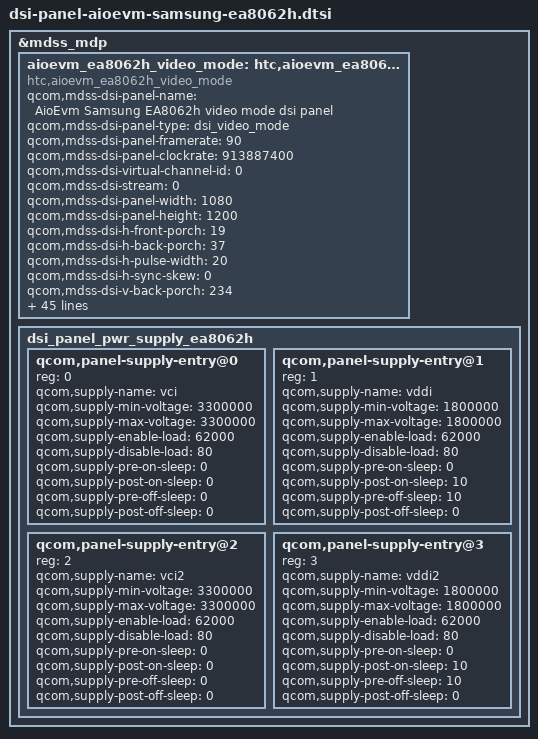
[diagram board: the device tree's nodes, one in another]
/* Copyright (c) 2014-2015, The Linux Foundation. All rights reserved.
 *
 * This program is free software; you can redistribute it and/or modify
 * it under the terms of the GNU General Public License version 2 and
 * only version 2 as published by the Free Software Foundation.
 *
 * This program is distributed in the hope that it will be useful,
 * but WITHOUT ANY WARRANTY; without even the implied warranty of
 * MERCHANTABILITY or FITNESS FOR A PARTICULAR PURPOSE.  See the
 * GNU General Public License for more details.
 */

&mdss_mdp {
    aioevm_ea8062h_video_mode: htc,aioevm_ea8062h_video_mode {
        compatible = "htc,aioevm_ea8062h_video_mode";
        qcom,mdss-dsi-panel-name = "AioEvm Samsung EA8062h video mode dsi panel";
        qcom,mdss-dsi-panel-type = "dsi_video_mode";
        qcom,mdss-dsi-panel-framerate = <90>;
        qcom,mdss-dsi-panel-clockrate = <913887400>;
        qcom,mdss-dsi-virtual-channel-id = <0>;
        qcom,mdss-dsi-stream = <0>;
        qcom,mdss-dsi-panel-width = <1080>;
        qcom,mdss-dsi-panel-height = <1200>;
        qcom,mdss-dsi-h-front-porch = <19>;
        qcom,mdss-dsi-h-back-porch = <37>;
        qcom,mdss-dsi-h-pulse-width = <20>;
        qcom,mdss-dsi-h-sync-skew = <0>;
        qcom,mdss-dsi-v-back-porch = <234>;
        qcom,mdss-dsi-v-front-porch = <28>;
        qcom,mdss-dsi-v-pulse-width = <2>;
        qcom,mdss-dsi-h-left-border = <0>;
        qcom,mdss-dsi-h-right-border = <0>;
        qcom,mdss-dsi-v-top-border = <0>;
        qcom,mdss-dsi-v-bottom-border = <0>;
        qcom,mdss-pan-physical-width-dimension  = <61>;
        qcom,mdss-pan-physical-height-dimension = <68>;
        qcom,mdss-dsi-bpp = <24>;
        qcom,mdss-dsi-color-order = "rgb_swap_rgb";
        qcom,mdss-dsi-underflow-color = <0xff>;
        qcom,mdss-dsi-border-color = <0>;
        qcom,mdss-dsi-h-sync-pulse = <0>;
        qcom,mdss-dsi-traffic-mode = "burst_mode";
        qcom,mdss-dsi-bllp-eof-power-mode;
        qcom,mdss-dsi-bllp-power-mode;
        qcom,mdss-dsi-tx-eot-append;
        qcom,mdss-dsi-lane-0-state;
        qcom,mdss-dsi-lane-1-state;
        qcom,mdss-dsi-lane-2-state;
        qcom,mdss-dsi-lane-3-state;
        qcom,mdss-dsi-dma-trigger = "trigger_sw";
        qcom,mdss-dsi-panel-timings = [D6 32 22 00 62 66 26 36 28 03 04 00]; /* Redundant for msm8996 */

        qcom,mdss-dsi-panel-timings-phy-v2 = [
            24 1F 08 09 05 03 04 a0
            24 1F 08 09 05 03 04 a0
            24 1F 08 09 05 03 04 a0
            24 1F 08 09 05 03 04 a0
            24 1C 08 09 05 03 04 a0    // Clk Lane
        ];
        qcom,mdss-dsi-t-clk-post = <0x0E>;
        qcom,mdss-dsi-t-clk-pre = <0x31>;

        qcom,mdss-dsi-reset-sequence = <1 1>, <0 1>, <1 10>;
        qcom,mdss-dsi-bl-pmic-control-type = "bl_ctrl_dcs";
        qcom,mdss-dsi-bl-min-level = <1>;
        qcom,mdss-dsi-bl-max-level = <255>;
        qcom,cmd-sync-wait-broadcast;

        qcom,mdss-dsi-on-command = [
            39 01 00 00 00 00 03 F0 5A 5A /* LEVEL 2 KEY Unlock */
            39 01 00 00 00 00 0A F2 00 00 00 00 00 04 38 04 B0 /* Resolution Setting */
            39 01 00 00 00 00 05 B2 04 C3 04 C3 /* AID Control (GI 16.6%) */
            39 01 00 00 00 00 03 B9 36 15 /* Source Control */
            39 01 00 00 00 00 03 C1 00 20 /* Pentile Control */
            39 01 00 00 00 00 03 F4 02 10 /* Power Control */
            39 01 00 00 00 00 08 B8 00 5A 74 03 00 00 19 /* VLIN1 Control */
            39 01 00 00 00 00 02 F7 01 /* Ltps Update */
            39 01 00 00 00 00 03 F0 A5 A5 /* LEVEL 2 KEY Lock */
            39 01 00 00 00 00 02 53 20  /* Dimming Control */
            39 01 00 00 00 00 02 51 8C /* WRDISBV ( 137 nits ) */
            39 01 00 00 00 00 03 FC 5A 5A /* LEVEL 3 KEY Unlock */
            39 01 00 00 00 00 02 B0 05 /* Global para */
            39 01 00 00 00 00 02 D1 80 /* OTP loading */
            39 01 00 00 78 00 02 11 00 /* Sleep Out & Delay 120 ms*/
            39 01 00 00 00 00 03 FC A5 A5 /* LEVEL 3 KEY Lock */
            39 01 00 00 00 00 03 F1 5A 5A /* OTP KEY Unlock */
            39 01 00 00 00 00 02 B0 01 /* Global para */
            39 01 00 00 00 00 02 CC 0A  /* TE pin normally low */
            39 01 00 00 00 00 03 F1 5A 5A /* OTP KEY Lock */
            39 01 00 00 00 00 02 29 00 /* Display On */
        ];

        qcom,mdss-dsi-off-command = [
            39 01 00 00 00 23 02 28 00 /* Display Off  & Delay 35 ms*/
            39 01 00 00 00 78 02 10 00 /* Sleep In & Delay 120 ms*/
        ];

        qcom,panel-supply-entries = <&dsi_panel_pwr_supply_ea8062h>;
        qcom,mdss-dsi-on-command-state = "dsi_lp_mode";
        qcom,mdss-dsi-off-command-state = "dsi_lp_mode";
        qcom,cont-splash-enabled;
        qcom,mdss-dsi-lp11-init;
        htc,mdss-dsi-lp11-init-delay-us = <25000>;
    };

    dsi_panel_pwr_supply_ea8062h: dsi_panel_pwr_supply_ea8062h {
        #address-cells = <1>;
        #size-cells = <0>;

        qcom,panel-supply-entry@0 {
            reg = <0>;
            qcom,supply-name = "vci";
            qcom,supply-min-voltage = <3300000>;
            qcom,supply-max-voltage = <3300000>;
            qcom,supply-enable-load = <62000>;
            qcom,supply-disable-load = <80>;
            qcom,supply-pre-on-sleep = <0>;
            qcom,supply-post-on-sleep = <0>;
            qcom,supply-pre-off-sleep = <0>;
            qcom,supply-post-off-sleep = <0>;
        };

        qcom,panel-supply-entry@1 {
            reg = <1>;
            qcom,supply-name = "vddi";
            qcom,supply-min-voltage = <1800000>;
            qcom,supply-max-voltage = <1800000>;
            qcom,supply-enable-load = <62000>;
            qcom,supply-disable-load = <80>;
            qcom,supply-pre-on-sleep = <0>;
            qcom,supply-post-on-sleep = <10>; //10ms
            qcom,supply-pre-off-sleep = <10>; //10ms
            qcom,supply-post-off-sleep = <0>;
        };
        qcom,panel-supply-entry@2 {
            reg = <2>;
            qcom,supply-name = "vci2";
            qcom,supply-min-voltage = <3300000>;
            qcom,supply-max-voltage = <3300000>;
            qcom,supply-enable-load = <62000>;
            qcom,supply-disable-load = <80>;
            qcom,supply-pre-on-sleep = <0>;
            qcom,supply-post-on-sleep = <0>;
            qcom,supply-pre-off-sleep = <0>;
            qcom,supply-post-off-sleep = <0>;
        };

        qcom,panel-supply-entry@3 {
            reg = <3>;
            qcom,supply-name = "vddi2";
            qcom,supply-min-voltage = <1800000>;
            qcom,supply-max-voltage = <1800000>;
            qcom,supply-enable-load = <62000>;
            qcom,supply-disable-load = <80>;
            qcom,supply-pre-on-sleep = <0>;
            qcom,supply-post-on-sleep = <10>; //10ms
            qcom,supply-pre-off-sleep = <10>; //10ms
            qcom,supply-post-off-sleep = <0>;
        };
    };
};
